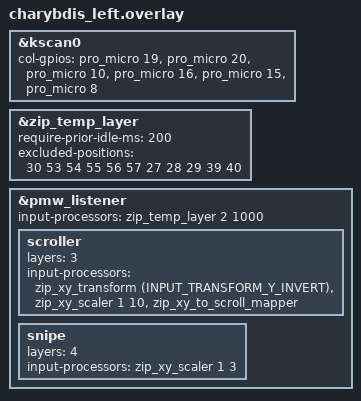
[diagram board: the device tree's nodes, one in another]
/*
 * Copyright (c) 2020 ZMK Contributors
 *
 * SPDX-License-Identifier: MIT
 */

#include "charybdis.dtsi"

#include <input/processors.dtsi>
#include <dt-bindings/zmk/input_transform.h>

&kscan0 {
	col-gpios
		= <&pro_micro 19 (GPIO_ACTIVE_HIGH | GPIO_PULL_DOWN)>
		, <&pro_micro 20 (GPIO_ACTIVE_HIGH | GPIO_PULL_DOWN)>
		, <&pro_micro 10 (GPIO_ACTIVE_HIGH | GPIO_PULL_DOWN)>
		, <&pro_micro 16 (GPIO_ACTIVE_HIGH | GPIO_PULL_DOWN)>
		, <&pro_micro 15 (GPIO_ACTIVE_HIGH | GPIO_PULL_DOWN)>
		, <&pro_micro 8 (GPIO_ACTIVE_HIGH | GPIO_PULL_DOWN)>
		;
};


// https://github.com/kot149/zenn-contents/blob/main/articles/zmk-auto-mouse-layer.md#%E3%82%AD%E3%83%BC%E5%85%A5%E5%8A%9B%E4%B8%AD%E3%81%AE%E3%82%AA%E3%83%BC%E3%83%88%E3%83%9E%E3%82%A6%E3%82%B9%E3%83%AC%E3%82%A4%E3%83%A4%E3%83%BC%E8%AA%A4%E7%88%86%E9%98%B2%E6%AD%A2
&zip_temp_layer {
		// 需要在输入事件发生后200ms idle，再碰球才会触发 auto_mouse，避免误触发
		require-prior-idle-ms = <200>;
		// 除了这些鼠标键，按下其他按键立刻退出 auto_mouse
		excluded-positions = <
				30
				53 54 55 56 57 // right thumbs

				27 28 29
				39 40
		>;
};

&pmw_listener {
	status = "okay";

	// when layer 3 is active, the trackball will act as a mouse wheel
	scroller {
		layers = <3>;
		input-processors = <&zip_xy_transform (INPUT_TRANSFORM_Y_INVERT)  &zip_xy_scaler 1 10  &zip_xy_to_scroll_mapper>;
	};
	// default when layer 4 is active, the trackball will move more slowly
		snipe {
		layers =<4>;
		input-processors = <&zip_xy_scaler 1 3>;
	};
	// temp layer when trackball is used, 2 is layer index, and 2000 is the time which the layer will deactivate when no input events is emitted
	input-processors = <&zip_temp_layer 2 1000>;
};
